# STM32H743 register map
File version: 2.4
CPU: CM7 r0p1, little endian, MPU, FPU, 4 interrupt priority bits
Registers are 32-bit, read-write, reset 0x0 unless marked. A register's access mark holds for its fields unless they carry their own. Offsets are from the block's base; [hi:lo] are bit positions; {n}, {i} and the like mark numbered series; 'fields as' and 'values as' point back to an identical list.

## HRTIM_TIMA — 高分辨率定时器：TIMA
Base 0x40017480
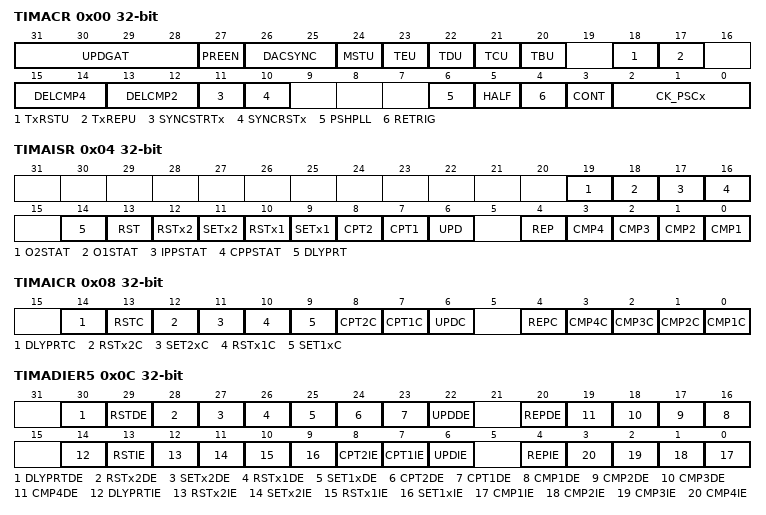
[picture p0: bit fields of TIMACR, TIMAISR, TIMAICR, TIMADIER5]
0x00 TIMACR — 定时器 x 控制寄存器
  [31:28] UPDGAT — 更新门控
  [27] PREEN — 预装载使能
  [26:25] DACSYNC — DAC 同步
  [24] MSTU — 主定时器更新
  [23] TEU
  [22] TDU
  [21] TCU
  [20] TBU
  [18] TxRSTU — 定时器 x 复位更新
  [17] TxREPU — 定时器 x 重复更新
  [15:14] DELCMP4 — 延迟 CMP4 模式
  [13:12] DELCMP2 — 延迟 CMP2 模式
  [11] SYNCSTRTx — 同步启动定时器 x
  [10] SYNCRSTx — 同步复位定时器 x
  [6] PSHPLL — 推挽模式使能
  [5] HALF — 半模式使能
  [4] RETRIG — 可重触发模式
  [3] CONT — 连续模式
  [2:0] CK_PSCx — HRTIM 定时器 x 时钟预分频器
0x04 TIMAISR ro — 定时器 x 中断状态寄存器
  [19] O2STAT — 输出 2 状态
  [18] O1STAT — 输出 1 状态
  [17] IPPSTAT — 空闲推挽状态
  [16] CPPSTAT — 当前推挽状态
  [14] DLYPRT — 延迟保护标志
  [13] RST — 复位中断标志
  [12] RSTx2 — 输出 2 复位中断标志
  [11] SETx2 — 输出 2 置位中断标志
  [10] RSTx1 — 输出 1 复位中断标志
  [9] SETx1 — 输出 1 置位中断标志
  [8] CPT2 — 捕获 2 中断标志
  [7] CPT1 — 捕获 1 中断标志
  [6] UPD — 更新中断标志
  [4] REP — 重复中断标志
  [n-1] CMP{n} (n=1..4) — 比较 {n} 中断标志
0x08 TIMAICR wo — 定时器 x 中断清除寄存器
  [14] DLYPRTC — 延迟保护标志清除
  [13] RSTC — 复位中断标志清除
  [12] RSTx2C — 输出 2 复位标志清除
  [11] SET2xC — 输出 2 置位标志清除
  [10] RSTx1C — 输出 1 复位标志清除
  [9] SET1xC — 输出 1 置位标志清除
  [8] CPT2C — 捕获 2 中断标志清除
  [7] CPT1C — 捕获 1 中断标志清除
  [6] UPDC — 更新中断标志清除
  [4] REPC — 重复中断标志清除
  [n-1] CMP{n}C (n=1..4) — 比较 {n} 中断标志清除
0x0C TIMADIER5 — TIMxDIER5
  [30] DLYPRTDE, [29] RSTDE, [28] RSTx2DE, [27] SETx2DE, [26] RSTx1DE, [25] SET1xDE, [24] CPT2DE, [23] CPT1DE, [22] UPDDE, [20] REPDE, [n+15] CMP{n}DE (n=1..4), [14] DLYPRTIE, [13] RSTIE, [12] RSTx2IE, [11] SETx2IE, [10] RSTx1IE, [9] SET1xIE, [8] CPT2IE, [7] CPT1IE, [6] UPDIE, [4] REPIE, [n-1] CMP{n}IE (n=1..4)
0x10 CNTAR — 定时器 x 计数器寄存器
  [15:0] CNTx — 定时器 x 计数器值
0x14 PERAR reset 0xFFFF — 定时器 x 周期寄存器
  [15:0] PERx — 定时器 x 周期值
0x18 REPAR — 定时器 x 重复寄存器
  [7:0] REPx — 定时器 x 重复计数器值
0x1C CMP1AR — 定时器 x 比较 1 寄存器
  [15:0] CMP1x — 定时器 x 比较 1 值
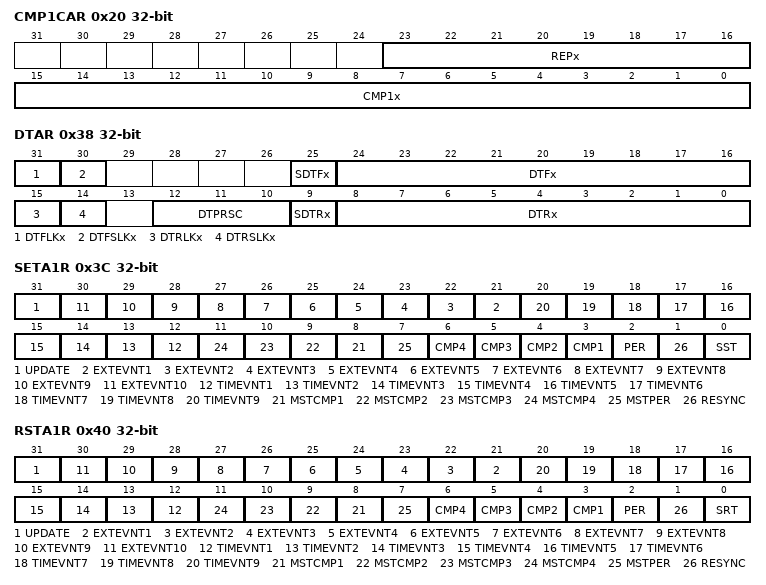
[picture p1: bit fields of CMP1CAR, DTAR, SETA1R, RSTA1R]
0x20 CMP1CAR — 定时器 x 比较 1 复合寄存器
  [23:16] REPx — 定时器 x 重复值（来自 HRTIM_REPx 寄存器的别名）
  [15:0] CMP1x — 定时器 x 比较 1 值
{0x1C+4i} CMP{i}AR (i=2..4) — 定时器 x 比较 {i} 寄存器
  [15:0] CMP{i}x — 定时器 x 比较 {i} 值
0x30 CPT1AR ro — 定时器 x 捕获 1 寄存器
  [15:0] CPT1x — 定时器 x 捕获 1 值
0x34 CPT2AR ro — 定时器 x 捕获 2 寄存器
  [15:0] CPT2x — 定时器 x 捕获 2 值
0x38 DTAR — 定时器 x 死区寄存器
  [31] DTFLKx — 死区下降沿锁定
  [30] DTFSLKx — 死区下降沿符号锁定
  [25] SDTFx — 带符号死区下降沿值
  [24:16] DTFx — 死区下降沿值
  [15] DTRLKx — 死区上升沿锁定
  [14] DTRSLKx — 死区上升沿符号锁定
  [12:10] DTPRSC — 死区预分频器
  [9] SDTRx — 带符号死区上升沿值
  [8:0] DTRx — 死区上升沿值
0x3C SETA1R — 定时器 x 输出 1 置位寄存器
  [31] UPDATE — 寄存器更新（将预装载值传输到活动寄存器）
  [n+20] EXTEVNT{n} (n=1..10) — 外部事件 {n}
  [n+11] TIMEVNT{n} (n=1..9) — 定时器事件 {n}
  [n+7] MSTCMP{n} (n=1..4) — 主定时器比较 {n}
  [7] MSTPER — 主定时器周期
  [n+2] CMP{n} (n=1..4) — 定时器 A 比较 {n}
  [2] PER — 定时器 A 周期
  [1] RESYNC — 定时器 A 再同步
  [0] SST — 软件置位触发
0x40 RSTA1R — 定时器 x 输出 1 复位寄存器
  [31] UPDATE, [n+20] EXTEVNT{n} (n=1..10), [n+11] TIMEVNT{n} (n=1..9), [n+7] MSTCMP{n} (n=1..4), [7] MSTPER, [n+2] CMP{n} (n=1..4), [2] PER, [1] RESYNC, [0] SRT
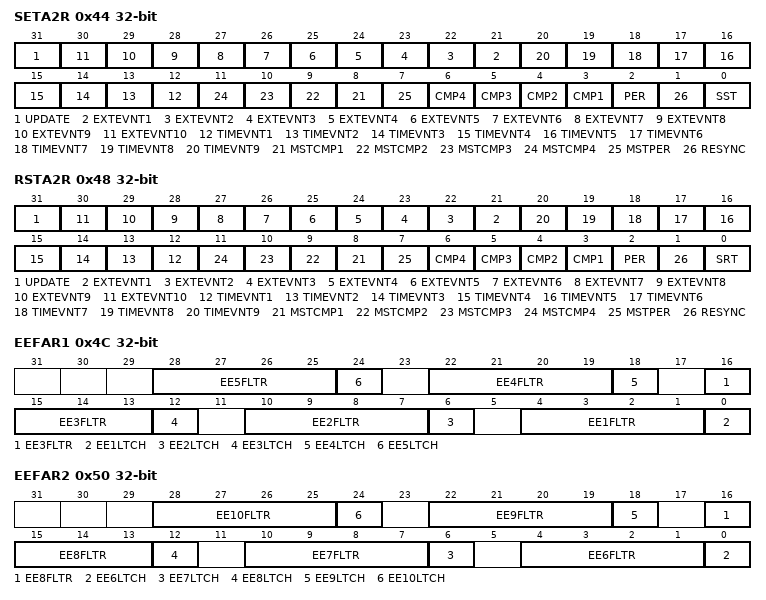
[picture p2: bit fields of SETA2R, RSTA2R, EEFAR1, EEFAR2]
0x44 SETA2R — 定时器 x 输出 2 置位寄存器
  [31] UPDATE, [n+20] EXTEVNT{n} (n=1..10), [n+11] TIMEVNT{n} (n=1..9), [n+7] MSTCMP{n} (n=1..4), [7] MSTPER, [n+2] CMP{n} (n=1..4), [2] PER, [1] RESYNC, [0] SST
0x48 RSTA2R — 定时器 x 输出 2 复位寄存器
  fields as RSTA1R
0x4C EEFAR1 — 定时器 x 外部事件滤波寄存器 1
  [6n-2:6n-5] EE{n}FLTR (n=1..5) — 外部事件 {n} 滤波器
  [6n-6] EE{n}LTCH (n=1..5) — 外部事件 {n} 锁存器
0x50 EEFAR2 — 定时器 x 外部事件滤波寄存器 2
  [6n-32:6n-35] EE{n}FLTR (n=6..10) — 外部事件 {n} 滤波器
  [6n-36] EE{n}LTCH (n=6..10) — 外部事件 {n} 锁存器
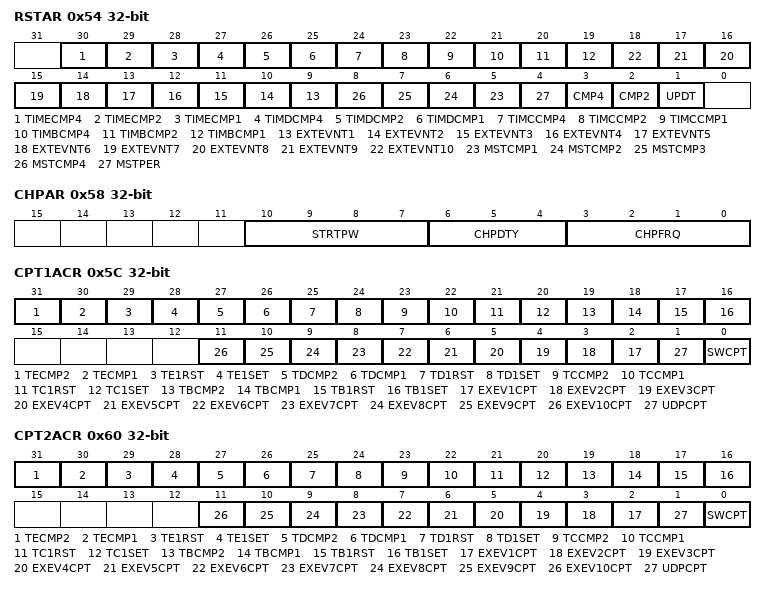
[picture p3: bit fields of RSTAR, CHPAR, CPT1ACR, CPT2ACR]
0x54 RSTAR — 定时器 A 复位寄存器
  [30] TIMECMP4 — 定时器 E 比较 4
  [29] TIMECMP2 — 定时器 E 比较 2
  [28] TIMECMP1 — 定时器 E 比较 1
  [27] TIMDCMP4 — 定时器 D 比较 4
  [26] TIMDCMP2 — 定时器 D 比较 2
  [25] TIMDCMP1 — 定时器 D 比较 1
  [24] TIMCCMP4 — 定时器 C 比较 4
  [23] TIMCCMP2 — 定时器 C 比较 2
  [22] TIMCCMP1 — 定时器 C 比较 1
  [21] TIMBCMP4 — 定时器 B 比较 4
  [20] TIMBCMP2 — 定时器 B 比较 2
  [19] TIMBCMP1 — 定时器 B 比较 1
  [n+8] EXTEVNT{n} (n=1..10) — 外部事件 {n}
  [n+4] MSTCMP{n} (n=1..4) — 主定时器比较 {n}
  [4] MSTPER — 主定时器周期
  [3] CMP4 — 定时器 A 比较 4 复位
  [2] CMP2 — 定时器 A 比较 2 复位
  [1] UPDT — 定时器 A 更新复位
0x58 CHPAR — 定时器 x 斩波寄存器
  [10:7] STRTPW
  [6:4] CHPDTY — 定时器 x 斩波占空比值
  [3:0] CHPFRQ — 定时器 x 载波频率值
0x5C CPT1ACR — 定时器 x 捕获 2 控制寄存器
  [31] TECMP2 — 定时器 E 比较 2
  [30] TECMP1 — 定时器 E 比较 1
  [29] TE1RST — 定时器 E 输出 1 复位
  [28] TE1SET — 定时器 E 输出 1 置位
  [27] TDCMP2 — 定时器 D 比较 2
  [26] TDCMP1 — 定时器 D 比较 1
  [25] TD1RST — 定时器 D 输出 1 复位
  [24] TD1SET — 定时器 D 输出 1 置位
  [23] TCCMP2 — 定时器 C 比较 2
  [22] TCCMP1 — 定时器 C 比较 1
  [21] TC1RST — 定时器 C 输出 1 复位
  [20] TC1SET — 定时器 C 输出 1 置位
  [19] TBCMP2 — 定时器 B 比较 2
  [18] TBCMP1 — 定时器 B 比较 1
  [17] TB1RST — 定时器 B 输出 1 复位
  [16] TB1SET — 定时器 B 输出 1 置位
  [n+1] EXEV{n}CPT (n=1..10) — 外部事件 {n} 捕获
  [1] UDPCPT — 更新捕获
  [0] SWCPT — 软件捕获
0x60 CPT2ACR — CPT2xCR
  fields as CPT1ACR
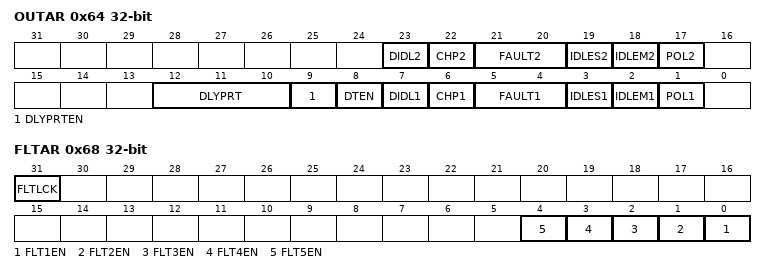
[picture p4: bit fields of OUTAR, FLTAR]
0x64 OUTAR — 定时器 x 输出寄存器
  [23] DIDL2 — 输出 2 突发模式空闲进入时的死区
  [22] CHP2 — 输出 2 斩波使能
  [21:20] FAULT2 — 输出 2 故障状态
  [19] IDLES2 — 输出 2 空闲状态
  [18] IDLEM2 — 输出 2 空闲模式
  [17] POL2 — 输出 2 极性
  [12:10] DLYPRT — 延迟保护
  [9] DLYPRTEN — 延迟保护使能
  [8] DTEN — 死区使能
  [7] DIDL1 — 输出 1 突发模式空闲进入时的死区
  [6] CHP1 — 输出 1 斩波使能
  [5:4] FAULT1 — 输出 1 故障状态
  [3] IDLES1 — 输出 1 空闲状态
  [2] IDLEM1 — 输出 1 空闲模式
  [1] POL1 — 输出 1 极性
0x68 FLTAR — 定时器 x 故障寄存器
  [31] FLTLCK — 故障源锁定
  [n-1] FLT{n}EN (n=1..5) — 故障 {n} 使能
